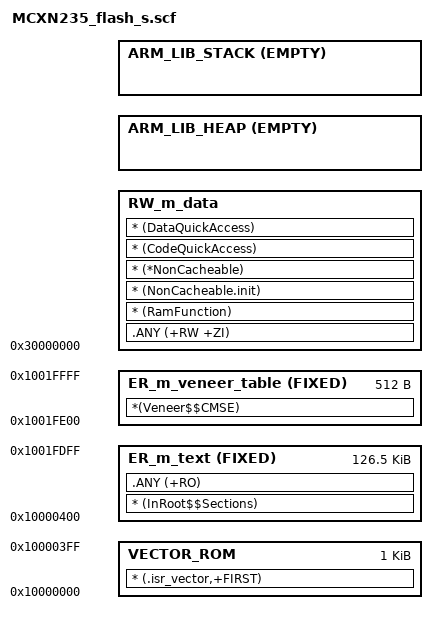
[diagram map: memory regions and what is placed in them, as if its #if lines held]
#!armclang --target=arm-arm-none-eabi -march=armv8-m.main -E -x c
/*
** ###################################################################
**     Processors:          MCXN235VDF
**                          MCXN235VKL
**                          MCXN235VNL
**                          MCXN235VPB
**
**     Compiler:            Keil ARM C/C++ Compiler
**     Reference manual:    MCXN23XRM
**     Version:             rev. 1.0, 2021-08-03
**     Build:               b250427
**
**     Abstract:
**         Linker file for the Keil ARM C/C++ Compiler
**
**     Copyright 2016 Freescale Semiconductor, Inc.
**     Copyright 2016-2025 NXP
**     SPDX-License-Identifier: BSD-3-Clause
**
**     http:                 www.nxp.com
**     mail:                 support@nxp.com
**
** ###################################################################
*/


/* USB BDT size */
#define usb_bdt_size                   0x0
/* Sizes */
#if (defined(__stack_size__))
  #define Stack_Size                   __stack_size__
#else
  #define Stack_Size                   0x0400
#endif

#if (defined(__heap_size__))
  #define Heap_Size                    __heap_size__
#else
  #define Heap_Size                    0x0400
#endif


#define  m_interrupts_start            0x10000000
#define  m_interrupts_size             0x00000400

#define  m_text_start                  0x10000400
#define  m_text_size                   0x0001FA00


/* 512B - memory for veneer table (NSC - secure, non-secure callable memory) */
#define m_veneer_table_start           0x1001FE00
#define m_veneer_table_size            0x00000200
#define  m_data_start                  0x30000000
#define  m_data_size                   0x00008000


LR_m_text m_interrupts_start m_interrupts_size+m_text_size+m_veneer_table_size {   ; load region size_region

  VECTOR_ROM m_interrupts_start m_interrupts_size { ; load address = execution address
    * (.isr_vector,+FIRST)
  }

  ER_m_text m_text_start FIXED m_text_size { ; load address = execution address
    * (InRoot$$Sections)
    .ANY (+RO)
  }

  RW_m_data m_data_start m_data_size-Stack_Size-Heap_Size { ; RW data
    .ANY (+RW +ZI)
    * (RamFunction)
    * (NonCacheable.init)
    * (*NonCacheable)
    * (CodeQuickAccess)
    * (DataQuickAccess)
  }

  ARM_LIB_HEAP +0 EMPTY Heap_Size {    ; Heap region growing up
  }
  ARM_LIB_STACK m_data_start+m_data_size EMPTY -Stack_Size { ; Stack region growing down
  }

  ER_m_veneer_table m_veneer_table_start FIXED m_veneer_table_size {; veneer table
    *(Veneer$$CMSE)
  }
}
